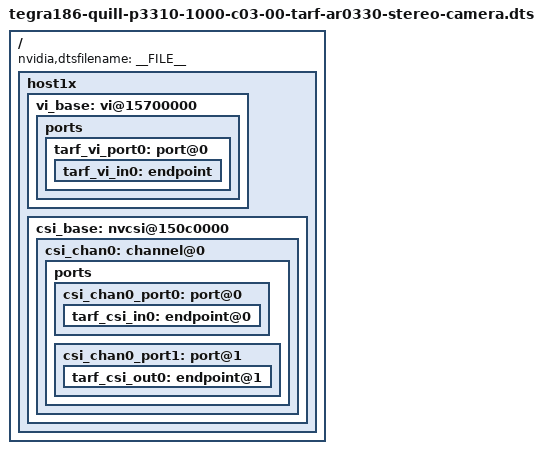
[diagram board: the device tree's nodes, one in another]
/*
 * tegra186-quill-p3310-1000-c03-00-tarf-ar0330-stereo-camera.dts: DTS file for Quill
 * to enable tarf ar0330 stereo camera.
 *
 * Copyright (c) 2016, NVIDIA CORPORATION.  All rights reserved.
 *
 * This program is free software; you can redistribute it and/or modify
 * it under the terms of the GNU General Public License as published by
 * the Free Software Foundation; version 2 of the License.
 *
 * This program is distributed in the hope that it will be useful, but WITHOUT
 * ANY WARRANTY; without even the implied warranty of MERCHANTABILITY or
 * FITNESS FOR A PARTICULAR PURPOSE.  See the GNU General Public License for
 * more details.
 *
 */

#include "tegra186-quill-p3310-1000-c03-00-base.dts"
#include "quill-platforms/tegra186-quill-camera-tarf-stereo-ar0330.dtsi"

/ {
	nvidia,dtsfilename = __FILE__;

	host1x {
		vi_base: vi@15700000 {
			ports {
				tarf_vi_port0: port@0 {
					status = "okay";
					tarf_vi_in0: endpoint {
						status = "okay";
					};
				};
			};
		};
		csi_base: nvcsi@150c0000 {
			csi_chan0: channel@0 {
				status = "okay";
				ports {
					csi_chan0_port0: port@0 {
						status = "okay";
						tarf_csi_in0: endpoint@0 {
							status = "okay";
						};
					};
					csi_chan0_port1: port@1 {
						status = "okay";
						tarf_csi_out0: endpoint@1 {
							status = "okay";
						};
					};
				};
			};
		};
	};
};
